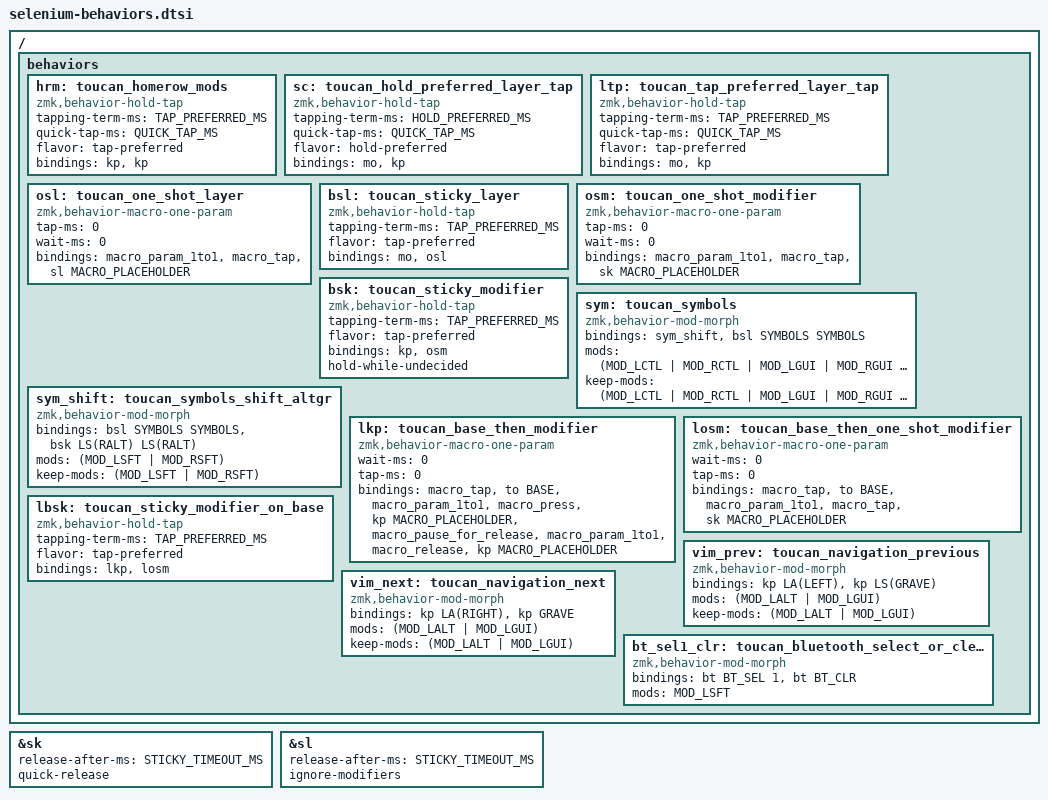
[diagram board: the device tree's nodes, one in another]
/*
 * SPDX-License-Identifier: MIT
 * Adapted from OneDeadKey/zmk-config-aekeynox, revision
 * 3cadeede766f31bc1e34d7c9d8ee918073cf8478:
 * include/aekeynox/hold_taps.dtsi and mappings.dtsi.
 * Copyright (c) 2024 The ZMK Contributors
 *
 * Permission is hereby granted, free of charge, to any person obtaining a copy
 * of this software and associated documentation files (the "Software"), to deal
 * in the Software without restriction, including without limitation the rights
 * to use, copy, modify, merge, publish, distribute, sublicense, and/or sell
 * copies of the Software, and to permit persons to whom the Software is
 * furnished to do so, subject to the following conditions:
 *
 * The above copyright notice and this permission notice shall be included in all
 * copies or substantial portions of the Software.
 *
 * THE SOFTWARE IS PROVIDED "AS IS", WITHOUT WARRANTY OF ANY KIND, EXPRESS OR
 * IMPLIED, INCLUDING BUT NOT LIMITED TO THE WARRANTIES OF MERCHANTABILITY,
 * FITNESS FOR A PARTICULAR PURPOSE AND NONINFRINGEMENT. IN NO EVENT SHALL THE
 * AUTHORS OR COPYRIGHT HOLDERS BE LIABLE FOR ANY CLAIM, DAMAGES OR OTHER
 * LIABILITY, WHETHER IN AN ACTION OF CONTRACT, TORT OR OTHERWISE, ARISING FROM,
 * OUT OF OR IN CONNECTION WITH THE SOFTWARE OR THE USE OR OTHER DEALINGS IN THE
 * SOFTWARE.
 */

#ifndef TOUCAN_SELENIUM_BEHAVIORS_DTSI
#define TOUCAN_SELENIUM_BEHAVIORS_DTSI

/* The keymap includes ZMK's <behaviors.dtsi> before this local file. */
#include <dt-bindings/zmk/keys.h>
#include <dt-bindings/zmk/bt.h>
#include "layers.h"
#include "timing.h"

/* Keep only Selenium's explicit overrides: release a sticky modifier on the
 * next key press, and preserve modifiers when chaining into a sticky layer.
 * Other sticky properties retain the defaults supplied by the pinned ZMK.
 */
&sk {
    release-after-ms = <STICKY_TIMEOUT_MS>;
    quick-release;
};

&sl {
    release-after-ms = <STICKY_TIMEOUT_MS>;
    ignore-modifiers;
};

/ {
    behaviors {
        hrm: toucan_homerow_mods {
            compatible = "zmk,behavior-hold-tap";
            #binding-cells = <2>;
            tapping-term-ms = <TAP_PREFERRED_MS>;
            quick-tap-ms = <QUICK_TAP_MS>;
            flavor = "tap-preferred";
            bindings = <&kp>, <&kp>;
        };

        sc: toucan_hold_preferred_layer_tap {
            compatible = "zmk,behavior-hold-tap";
            #binding-cells = <2>;
            tapping-term-ms = <HOLD_PREFERRED_MS>;
            quick-tap-ms = <QUICK_TAP_MS>;
            flavor = "hold-preferred";
            bindings = <&mo>, <&kp>;
        };

        ltp: toucan_tap_preferred_layer_tap {
            compatible = "zmk,behavior-hold-tap";
            #binding-cells = <2>;
            tapping-term-ms = <TAP_PREFERRED_MS>;
            quick-tap-ms = <QUICK_TAP_MS>;
            flavor = "tap-preferred";
            bindings = <&mo>, <&kp>;
        };

        osl: toucan_one_shot_layer {
            compatible = "zmk,behavior-macro-one-param";
            #binding-cells = <1>;
            tap-ms = <0>;
            wait-ms = <0>;
            bindings = <&macro_param_1to1>, <&macro_tap &sl MACRO_PLACEHOLDER>;
        };

        /* Bind both parameters to the same layer. No quick-tap override:
         * repeated taps must remain one-shots, as in the reference behavior.
         */
        bsl: toucan_sticky_layer {
            compatible = "zmk,behavior-hold-tap";
            #binding-cells = <2>;
            tapping-term-ms = <TAP_PREFERRED_MS>;
            flavor = "tap-preferred";
            bindings = <&mo>, <&osl>;
        };

        osm: toucan_one_shot_modifier {
            compatible = "zmk,behavior-macro-one-param";
            #binding-cells = <1>;
            tap-ms = <0>;
            wait-ms = <0>;
            bindings = <&macro_param_1to1>, <&macro_tap &sk MACRO_PLACEHOLDER>;
        };

        /* Bind both parameters to the same modifier. In particular,
         * &bsk LSHIFT LSHIFT acts immediately while the tap/hold is undecided.
         * There is no double-Shift CapsWord or CapsLock action.
         */
        bsk: toucan_sticky_modifier {
            compatible = "zmk,behavior-hold-tap";
            #binding-cells = <2>;
            tapping-term-ms = <TAP_PREFERRED_MS>;
            flavor = "tap-preferred";
            bindings = <&kp>, <&osm>;
            hold-while-undecided;
        };

        /* With Shift alone, Sym supplies Shift+AltGr for native Ergo-L
         * diacritics and Shift+AltGr+Space. Other shortcut modifiers keep Sym
         * on its ordinary Symbols-layer branch, matching Selenium.
         */
        sym: toucan_symbols {
            compatible = "zmk,behavior-mod-morph";
            #binding-cells = <0>;
            bindings = <&sym_shift>, <&bsl SYMBOLS SYMBOLS>;
            mods = <(MOD_LCTL | MOD_RCTL | MOD_LGUI | MOD_RGUI | MOD_LALT)>;
            keep-mods = <(MOD_LCTL | MOD_RCTL | MOD_LGUI | MOD_RGUI | MOD_LALT)>;
        };

        sym_shift: toucan_symbols_shift_altgr {
            compatible = "zmk,behavior-mod-morph";
            #binding-cells = <0>;
            bindings = <&bsl SYMBOLS SYMBOLS>, <&bsk LS(RALT) LS(RALT)>;
            mods = <(MOD_LSFT | MOD_RSFT)>;
            keep-mods = <(MOD_LSFT | MOD_RSFT)>;
        };

        /* Return from navigation to Base before applying AltGr. Pause until
         * release so a held modifier always gets its matching release event.
         */
        lkp: toucan_base_then_modifier {
            compatible = "zmk,behavior-macro-one-param";
            #binding-cells = <1>;
            wait-ms = <0>;
            tap-ms = <0>;
            bindings =
                <&macro_tap &to BASE>,
                <&macro_param_1to1>,
                <&macro_press &kp MACRO_PLACEHOLDER>,
                <&macro_pause_for_release>,
                <&macro_param_1to1>,
                <&macro_release &kp MACRO_PLACEHOLDER>;
        };

        losm: toucan_base_then_one_shot_modifier {
            compatible = "zmk,behavior-macro-one-param";
            #binding-cells = <1>;
            wait-ms = <0>;
            tap-ms = <0>;
            bindings =
                <&macro_tap &to BASE>,
                <&macro_param_1to1>,
                <&macro_tap &sk MACRO_PLACEHOLDER>;
        };

        lbsk: toucan_sticky_modifier_on_base {
            compatible = "zmk,behavior-hold-tap";
            #binding-cells = <2>;
            tapping-term-ms = <TAP_PREFERRED_MS>;
            flavor = "tap-preferred";
            bindings = <&lkp>, <&losm>;
        };

        vim_prev: toucan_navigation_previous {
            compatible = "zmk,behavior-mod-morph";
            #binding-cells = <0>;
            bindings = <&kp LA(LEFT)>, <&kp LS(GRAVE)>;
            mods = <(MOD_LALT | MOD_LGUI)>;
            keep-mods = <(MOD_LALT | MOD_LGUI)>;
        };

        vim_next: toucan_navigation_next {
            compatible = "zmk,behavior-mod-morph";
            #binding-cells = <0>;
            bindings = <&kp LA(RIGHT)>, <&kp GRAVE>;
            mods = <(MOD_LALT | MOD_LGUI)>;
            keep-mods = <(MOD_LALT | MOD_LGUI)>;
        };

        bt_sel1_clr: toucan_bluetooth_select_or_clear {
            compatible = "zmk,behavior-mod-morph";
            #binding-cells = <0>;
            bindings = <&bt BT_SEL 1>, <&bt BT_CLR>;
            mods = <MOD_LSFT>;
        };
    };
};

#endif /* TOUCAN_SELENIUM_BEHAVIORS_DTSI */
